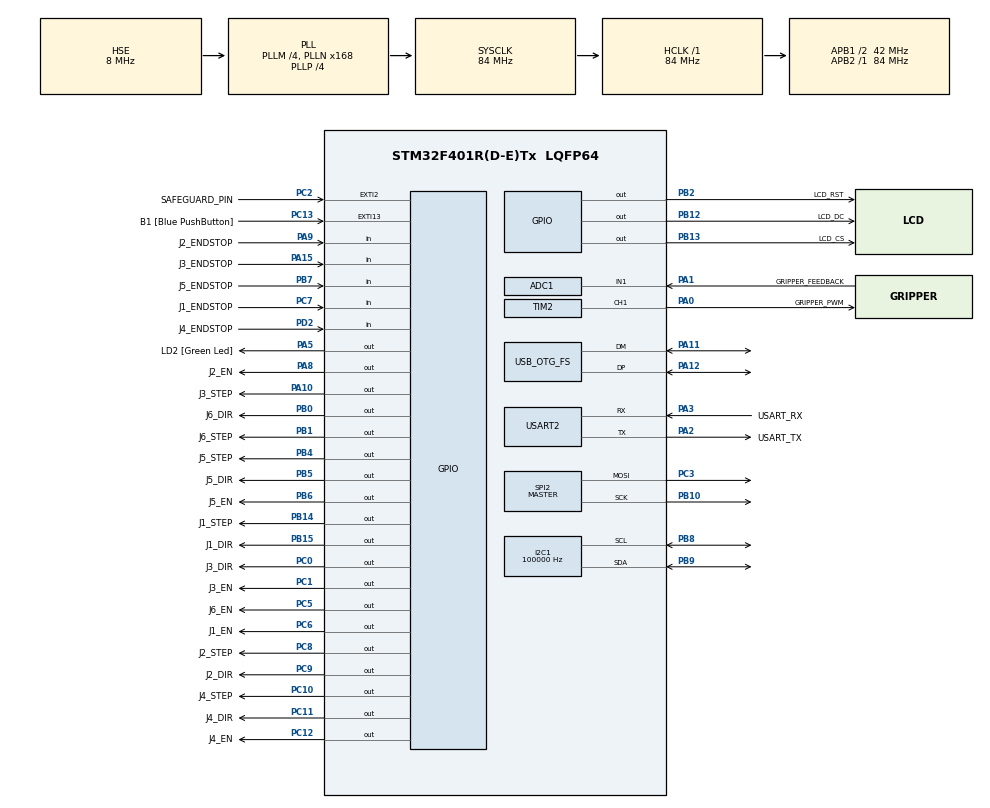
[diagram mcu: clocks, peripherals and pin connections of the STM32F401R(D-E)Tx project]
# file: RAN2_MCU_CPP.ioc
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ADC1.Channel-0\#ChannelRegularConversion=ADC_CHANNEL_1
ADC1.NbrOfConversionFlag=1
ADC1.Rank-0\#ChannelRegularConversion=1
ADC1.SamplingTime-0\#ChannelRegularConversion=ADC_SAMPLETIME_3CYCLES
ADC1.master=1
Dma.Request0=SPI2_TX
Dma.SPI2_TX.0.Direction=DMA_MEMORY_TO_PERIPH
Dma.SPI2_TX.0.FIFOMode=DMA_FIFOMODE_DISABLE
Dma.SPI2_TX.0.Instance=DMA1_Stream4
Dma.SPI2_TX.0.MemDataAlignment=DMA_MDATAALIGN_BYTE
Dma.SPI2_TX.0.MemInc=DMA_MINC_ENABLE
Dma.SPI2_TX.0.Mode=DMA_NORMAL
Dma.SPI2_TX.0.PeriphDataAlignment=DMA_PDATAALIGN_BYTE
Dma.SPI2_TX.0.PeriphInc=DMA_PINC_DISABLE
Dma.SPI2_TX.0.Priority=DMA_PRIORITY_LOW
I2C1.ClockSpeed=100000
I2C1.I2C_Mode=I2C_Standard
Mcu.Family=STM32F4
Mcu.Name=STM32F401R(D-E)Tx
Mcu.Package=LQFP64
NVIC.DMA1_Stream4_IRQn=true\:0\:0\:false\:false\:true\:false\:true\:true
NVIC.EXTI15_10_IRQn=true\:0\:0\:false\:false\:true\:true\:true\:true
NVIC.EXTI2_IRQn=true\:0\:0\:false\:false\:true\:true\:true\:true
NVIC.OTG_FS_IRQn=true\:0\:0\:false\:false\:true\:false\:true\:true
NVIC.PriorityGroup=NVIC_PRIORITYGROUP_3
NVIC.TIM1_BRK_TIM9_IRQn=true\:3\:0\:true\:false\:true\:true\:true\:true
NVIC.TIM1_TRG_COM_TIM11_IRQn=true\:0\:0\:false\:false\:true\:true\:true\:true
NVIC.TIM1_UP_TIM10_IRQn=true\:0\:0\:true\:false\:true\:true\:true\:true
NVIC.TIM3_IRQn=true\:0\:0\:false\:false\:true\:true\:true\:true
NVIC.TIM4_IRQn=true\:0\:0\:false\:false\:true\:true\:true\:true
NVIC.TIM5_IRQn=true\:0\:0\:false\:false\:true\:true\:true\:true
NVIC.USART2_IRQn=true\:0\:0\:false\:false\:true\:true\:true\:true
PA0-WKUP.GPIO_Label=GRIPPER_PWM
PA0-WKUP.Signal=S_TIM2_CH1_ETR
PA1.GPIO_Label=GRIPPER_FEEDBACK
PA1.Signal=ADCx_IN1
PA10.GPIO_Label=J3_STEP
PA10.Signal=GPIO_Output
PA11.Mode=Device_Only
PA11.Signal=USB_OTG_FS_DM
PA12.Mode=Device_Only
PA12.Signal=USB_OTG_FS_DP
PA13.GPIO_Label=TMS
PA13.Mode=Serial_Wire
PA13.Signal=SYS_JTMS-SWDIO
PA14.GPIO_Label=TCK
PA14.Mode=Serial_Wire
PA14.Signal=SYS_JTCK-SWCLK
PA15.GPIO_Label=J3_ENDSTOP
PA15.Signal=GPIO_Input
PA2.GPIO_Label=USART_TX
PA2.GPIO_Mode=GPIO_MODE_AF_PP
PA2.GPIO_PuPd=GPIO_NOPULL
PA2.GPIO_Speed=GPIO_SPEED_FREQ_LOW
PA2.Mode=Asynchronous
PA2.Signal=USART2_TX
PA3.GPIO_Label=USART_RX
PA3.GPIO_Mode=GPIO_MODE_AF_PP
PA3.GPIO_PuPd=GPIO_NOPULL
PA3.GPIO_Speed=GPIO_SPEED_FREQ_LOW
PA3.Mode=Asynchronous
PA3.Signal=USART2_RX
PA5.GPIO_Label=LD2 [Green Led]
PA5.GPIO_Mode=GPIO_MODE_OUTPUT_PP
PA5.GPIO_PuPd=GPIO_NOPULL
PA5.GPIO_Speed=GPIO_SPEED_FREQ_LOW
PA5.Signal=GPIO_Output
PA8.GPIO_Label=J2_EN
PA8.Signal=GPIO_Output
PA9.GPIO_Label=J2_ENDSTOP
PA9.Signal=GPIO_Input
PB0.GPIO_Label=J6_DIR
PB0.Signal=GPIO_Output
PB1.GPIO_Label=J6_STEP
PB1.Signal=GPIO_Output
PB10.Mode=TX_Only_Simplex_Unidirect_Master
PB10.Signal=SPI2_SCK
PB12.GPIO_Label=LCD_DC
PB12.Signal=GPIO_Output
PB13.GPIO_Label=LCD_CS
PB13.Signal=GPIO_Output
PB14.GPIO_Label=J1_STEP
PB14.GPIO_Speed=GPIO_SPEED_FREQ_VERY_HIGH
PB14.Signal=GPIO_Output
PB15.GPIO_Label=J1_DIR
PB15.Signal=GPIO_Output
PB2.GPIO_Label=LCD_RST
PB2.Signal=GPIO_Output
PB3.GPIO_Label=SWO
PB3.Signal=SYS_JTDO-SWO
PB4.GPIO_Label=J5_STEP
PB4.Signal=GPIO_Output
PB5.GPIO_Label=J5_DIR
PB5.Signal=GPIO_Output
PB6.GPIO_Label=J5_EN
PB6.Signal=GPIO_Output
PB7.GPIO_Label=J5_ENDSTOP
PB7.Signal=GPIO_Input
PB8.Mode=I2C
PB8.Signal=I2C1_SCL
PB9.Mode=I2C
PB9.Signal=I2C1_SDA
PC0.GPIO_Label=J3_DIR
PC0.Signal=GPIO_Output
PC1.GPIO_Label=J3_EN
PC1.Signal=GPIO_Output
PC10.GPIO_Label=J4_STEP
PC10.Signal=GPIO_Output
PC11.GPIO_Label=J4_DIR
PC11.Signal=GPIO_Output
PC12.GPIO_Label=J4_EN
PC12.Signal=GPIO_Output
PC13-ANTI_TAMP.GPIO_Label=B1 [Blue PushButton]
PC13-ANTI_TAMP.GPIO_ModeDefaultEXTI=GPIO_MODE_IT_FALLING
PC13-ANTI_TAMP.GPIO_PuPd=GPIO_NOPULL
PC13-ANTI_TAMP.Signal=GPXTI13
PC14-OSC32_IN.Mode=LSE-External-Oscillator
PC14-OSC32_IN.Signal=RCC_OSC32_IN
PC15-OSC32_OUT.Mode=LSE-External-Oscillator
PC15-OSC32_OUT.Signal=RCC_OSC32_OUT
PC2.GPIO_Label=SAFEGUARD_PIN
PC2.GPIO_ModeDefaultEXTI=GPIO_MODE_IT_FALLING
PC2.Signal=GPXTI2
PC3.Mode=TX_Only_Simplex_Unidirect_Master
PC3.Signal=SPI2_MOSI
PC5.GPIO_Label=J6_EN
PC5.Signal=GPIO_Output
PC6.GPIO_Label=J1_EN
PC6.Signal=GPIO_Output
PC7.GPIO_Label=J1_ENDSTOP
PC7.Signal=GPIO_Input
PC8.GPIO_Label=J2_STEP
PC8.Signal=GPIO_Output
PC9.GPIO_Label=J2_DIR
PC9.Signal=GPIO_Output
PD2.GPIO_Label=J4_ENDSTOP
PD2.Signal=GPIO_Input
PH0\ -\ OSC_IN.Mode=HSE-External-Clock-Source
PH0\ -\ OSC_IN.Signal=RCC_OSC_IN
PH1\ -\ OSC_OUT.Mode=HSE-External-Clock-Source
PH1\ -\ OSC_OUT.Signal=RCC_OSC_OUT
ProjectManager.HeapSize=0x400
ProjectManager.StackSize=0x4000
ProjectManager.TargetToolchain=STM32CubeIDE
RCC.48MHZClocksFreq_Value=48000000
RCC.AHBFreq_Value=84000000
RCC.APB1CLKDivider=RCC_HCLK_DIV2
RCC.APB1Freq_Value=42000000
RCC.APB1TimFreq_Value=84000000
RCC.APB2Freq_Value=84000000
RCC.APB2TimFreq_Value=84000000
RCC.CortexFreq_Value=84000000
RCC.HCLKFreq_Value=84000000
RCC.HSE_VALUE=8000000
RCC.HSI_VALUE=16000000
RCC.PLLM=4
RCC.PLLN=168
RCC.PLLP=RCC_PLLP_DIV4
RCC.PLLQ=7
RCC.SYSCLKFreq_VALUE=84000000
RCC.SYSCLKSource=RCC_SYSCLKSOURCE_PLLCLK
RCC.VCOOutputFreq_Value=336000000
SH.ADCx_IN1.0=ADC1_IN1,IN1
SH.S_TIM2_CH1_ETR.0=TIM2_CH1,PWM Generation1 CH1
SPI2.Direction=SPI_DIRECTION_2LINES
SPI2.Mode=SPI_MODE_MASTER
SPI2.VirtualType=VM_MASTER
TIM1.AutoReloadPreload=TIM_AUTORELOAD_PRELOAD_DISABLE
TIM1.Period=10000
TIM1.Prescaler=839
TIM10.Period=9999
TIM10.Prescaler=83
TIM11.Period=9999
TIM11.Prescaler=83
TIM2.Channel-PWM\ Generation1\ CH1=TIM_CHANNEL_1
TIM2.Period=20000
TIM2.Prescaler=83
TIM2.Pulse-PWM\ Generation1\ CH1=500
TIM3.Period=9999
TIM3.Prescaler=83
TIM4.Period=9999
TIM4.Prescaler=83
TIM5.Period=9999
TIM5.Prescaler=83
TIM9.Period=9999
TIM9.Prescaler=83
USART2.VirtualMode=VM_ASYNC
USB_DEVICE.CLASS_NAME_FS=CDC
USB_DEVICE.VirtualMode-CDC_FS=Cdc
USB_DEVICE.VirtualModeFS=Cdc_FS
USB_OTG_FS.VirtualMode=Device_Only
VP_TIM10_VS_ClockSourceINT.Mode=Enable_Timer
VP_TIM11_VS_ClockSourceINT.Mode=Enable_Timer
VP_TIM1_VS_ClockSourceINT.Mode=Internal
VP_TIM3_VS_ClockSourceINT.Mode=Internal
VP_TIM4_VS_ClockSourceINT.Mode=Internal
VP_TIM5_VS_ClockSourceINT.Mode=Internal
VP_TIM9_VS_ClockSourceINT.Mode=Internal
VP_USB_DEVICE_VS_USB_DEVICE_CDC_FS.Mode=CDC_FS
board=NUCLEO-F401RE

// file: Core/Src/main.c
/* USER CODE BEGIN Header */
/**
  ******************************************************************************
  * @file           : main.c
  * @brief          : Main program body
  ******************************************************************************
  * @attention
  *
  * Copyright (c) 2023 STMicroelectronics.
  * All rights reserved.
  *
  * This software is licensed under terms that can be found in the LICENSE file
  * in the root directory of this software component.
  * If no LICENSE file comes with this software, it is provided AS-IS.
  *
  ******************************************************************************
  */
/* USER CODE END Header */
#include "main.h"
#include "adc.h"
#include "dma.h"
#include "i2c.h"
#include "spi.h"
#include "tim.h"
#include "usart.h"
#include "usb_device.h"
#include "gpio.h"

/* USER CODE BEGIN Includes */

#include "../../RAN2/alt_main.hpp"

/* USER CODE END Includes */

void SystemClock_Config(void);

int main(void)
{

  /* MCU Configuration--------------------------------------------------------*/

  /* Reset of all peripherals, Initializes the Flash interface and the Systick. */
  HAL_Init();

  /* Configure the system clock */
  SystemClock_Config();

  /* Initialize all configured peripherals */
  MX_GPIO_Init();
  MX_DMA_Init();
  MX_USART2_UART_Init();
  MX_TIM10_Init();
  MX_TIM3_Init();
  MX_I2C1_Init();
  MX_TIM4_Init();
  MX_TIM5_Init();
  MX_TIM9_Init();
  MX_SPI2_Init();
  MX_TIM11_Init();
  MX_TIM1_Init();
  MX_ADC1_Init();
  MX_TIM2_Init();
  MX_USB_DEVICE_Init();
  /* USER CODE BEGIN 2 */

    alt_main();

  /* USER CODE END 2 */

  /* Infinite loop */
  while (1)
  {

  }
}

void SystemClock_Config(void)
{
  RCC_OscInitTypeDef RCC_OscInitStruct = {0};
  RCC_ClkInitTypeDef RCC_ClkInitStruct = {0};

  /** Configure the main internal regulator output voltage
  */
  __HAL_RCC_PWR_CLK_ENABLE();
  __HAL_PWR_VOLTAGESCALING_CONFIG(PWR_REGULATOR_VOLTAGE_SCALE2);

  /** Initializes the RCC Oscillators according to the specified parameters
  * in the RCC_OscInitTypeDef structure.
  */
  RCC_OscInitStruct.OscillatorType = RCC_OSCILLATORTYPE_HSE;
  RCC_OscInitStruct.HSEState = RCC_HSE_BYPASS;
  RCC_OscInitStruct.PLL.PLLState = RCC_PLL_ON;
  RCC_OscInitStruct.PLL.PLLSource = RCC_PLLSOURCE_HSE;
  RCC_OscInitStruct.PLL.PLLM = 4;
  RCC_OscInitStruct.PLL.PLLN = 168;
  RCC_OscInitStruct.PLL.PLLP = RCC_PLLP_DIV4;
  RCC_OscInitStruct.PLL.PLLQ = 7;
  if (HAL_RCC_OscConfig(&RCC_OscInitStruct) != HAL_OK)
  {
    Error_Handler();
  }

  /** Initializes the CPU, AHB and APB buses clocks
  */
  RCC_ClkInitStruct.ClockType = RCC_CLOCKTYPE_HCLK|RCC_CLOCKTYPE_SYSCLK
                              |RCC_CLOCKTYPE_PCLK1|RCC_CLOCKTYPE_PCLK2;
  RCC_ClkInitStruct.SYSCLKSource = RCC_SYSCLKSOURCE_PLLCLK;
  RCC_ClkInitStruct.AHBCLKDivider = RCC_SYSCLK_DIV1;
  RCC_ClkInitStruct.APB1CLKDivider = RCC_HCLK_DIV2;
  RCC_ClkInitStruct.APB2CLKDivider = RCC_HCLK_DIV1;

  if (HAL_RCC_ClockConfig(&RCC_ClkInitStruct, FLASH_LATENCY_2) != HAL_OK)
  {
    Error_Handler();
  }
}

void Error_Handler(void)
{
  __disable_irq();
  while (1)
  {
  }
}
